# STM32H745BGT6@M4 register map
File version: 1.0
Registers are 32-bit, access not given, reset 0x0 unless marked. A register's access mark holds for its fields unless they carry their own. Offsets are from the block's base; [hi:lo] are bit positions; {n}, {i} and the like mark numbered series.

## QUADSPI
Base 0x52005000
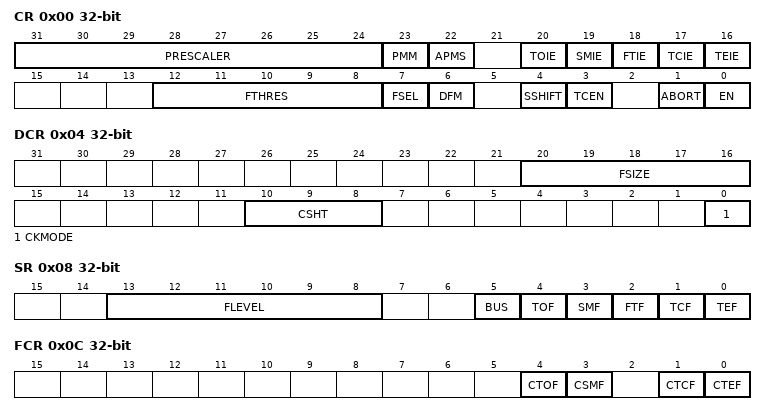
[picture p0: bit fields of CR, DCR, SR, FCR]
0x00 CR
  [31:24] PRESCALER, [23] PMM, [22] APMS, [20] TOIE, [19] SMIE, [18] FTIE, [17] TCIE, [16] TEIE, [12:8] FTHRES, [7] FSEL, [6] DFM, [4] SSHIFT, [3] TCEN, [1] ABORT, [0] EN
0x04 DCR
  [20:16] FSIZE, [10:8] CSHT, [0] CKMODE
0x08 SR
  [13:8] FLEVEL, [5] BUS, [4] TOF, [3] SMF, [2] FTF, [1] TCF, [0] TEF
0x0C FCR
  [4] CTOF, [3] CSMF, [1] CTCF, [0] CTEF
0x10 DLR
  [31:0] DL
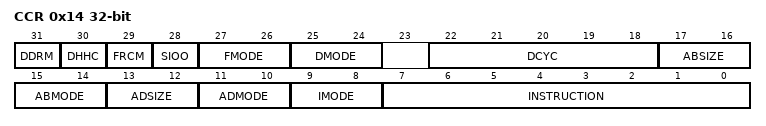
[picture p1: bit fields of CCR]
0x14 CCR
  [31] DDRM, [30] DHHC, [29] FRCM, [28] SIOO, [27:26] FMODE, [25:24] DMODE, [22:18] DCYC, [17:16] ABSIZE, [15:14] ABMODE, [13:12] ADSIZE, [11:10] ADMODE, [9:8] IMODE, [7:0] INSTRUCTION
0x18 AR
  [31:0] ADDRESS
0x1C ABR
  [31:0] ALTERNATE
0x20 DR
  [31:0] DATA
0x24 PSMKR
  [31:0] MASK
0x28 PSMAR
  [31:0] MATCH
0x2C PIR
  [15:0] INTERVAL
0x30 LPTR
  [15:0] TIMEOUT

## EXTI
Base 0x58000000
0x00 RTSR1
  [21:0] TR
0x04 FTSR1
  [21:0] TR
0x08 SWIER1
  [21:0] SWIER
0x0C D3PMR1
  [25:0] MR
0x10 D3PCR1L
  [31:0] PCS
0x14 D3PCR1H
  [19:6] PCS
0x20 RTSR2
  [19:17] TR
0x24 FTSR2
  [19:17] TR
0x28 SWIER2
  [19:17] SWIER
0x2C D3PMR2
  [21:2] MR
0x30 D3PCR2L
  [19:4] PCS
0x34 D3PCR2H
  [11:0] PCS
0x40 RTSR3
  [22:18] TR
0x44 FTSR3
  [22:18] TR
0x48 SWIER3
  [22:18] SWIER
0x4C D3PMR3
  [24] MR
0x50 D3PCR3L
0x54 D3PCR3H
  [17:16] PCS
0x80 C1IMR1
  [31:0] MR
0x84 C1EMR1
  [31:0] MR
0x88 C1PR1
  [21:0] PR
0x90 C1IMR2
  [31:0] MR
0x94 C1EMR2
  [31:0] MR
0x98 C1PR2
  [19:17] PR
0xA0 C1IMR3
  [24:0] MR
0xA4 C1EMR3
  [24:0] MR
0xA8 C1PR3
  [22:18] PR
0xC0 C2IMR1
  [31:0] MR
0xC4 C2EMR1
  [31:0] MR
0xC8 C2PR1
  [21:0] PR
0xD0 C2IMR2
  [31:0] MR
0xD4 C2EMR2
  [31:0] MR
0xD8 C2PR2
  [19:17] PR
0xE0 C2IMR3
  [24:0] MR
0xE4 C2EMR3
  [24:0] MR
0xE8 C2PR3
  [22:18] PR

## SYSCFG
Base 0x58000400
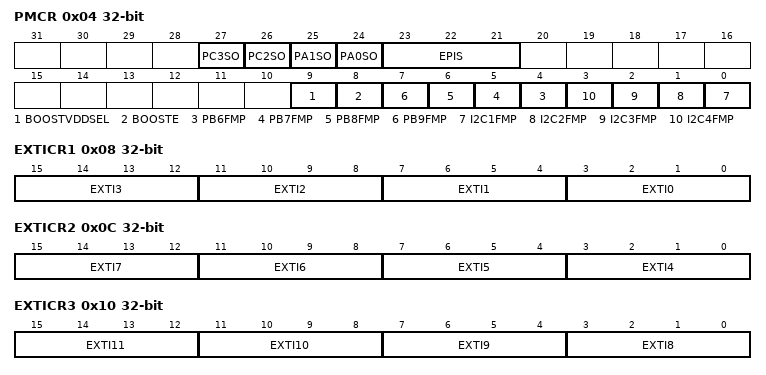
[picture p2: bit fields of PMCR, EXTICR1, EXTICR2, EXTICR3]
0x04 PMCR
  [27] PC3SO, [26] PC2SO, [25] PA1SO, [24] PA0SO, [23:21] EPIS, [9] BOOSTVDDSEL, [8] BOOSTE, [n-2] PB{n}FMP (n=6..9), [n-1] I2C{n}FMP (n=1..4)
0x08 EXTICR1
  [4n+3:4n] EXTI{n} (n=0..3)
0x0C EXTICR2
  [4n-13:4n-16] EXTI{n} (n=4..7)
0x10 EXTICR3
  [4n-29:4n-32] EXTI{n} (n=8..11)
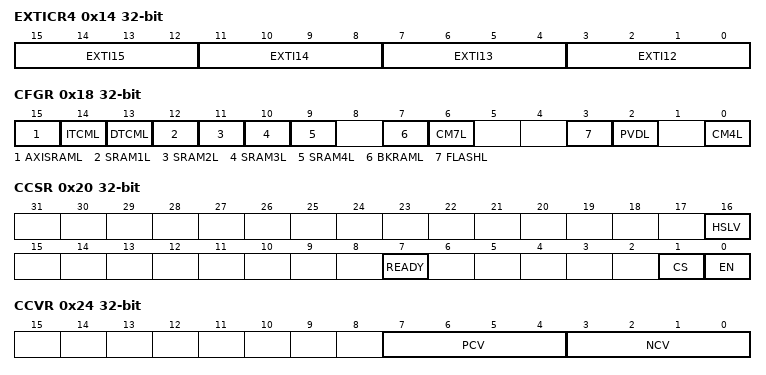
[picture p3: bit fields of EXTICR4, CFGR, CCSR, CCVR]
0x14 EXTICR4
  [4n-45:4n-48] EXTI{n} (n=12..15)
0x18 CFGR
  [15] AXISRAML, [14] ITCML, [13] DTCML, [13-n] SRAM{n}L (n=1..4), [7] BKRAML, [6] CM7L, [3] FLASHL, [2] PVDL, [0] CM4L
0x20 CCSR
  [16] HSLV, [7] READY, [1] CS, [0] EN
0x24 CCVR
  [7:4] PCV, [3:0] NCV
0x2C CCCR
  [0] ODEN
0x124 PKGR
  [3:0] PKG
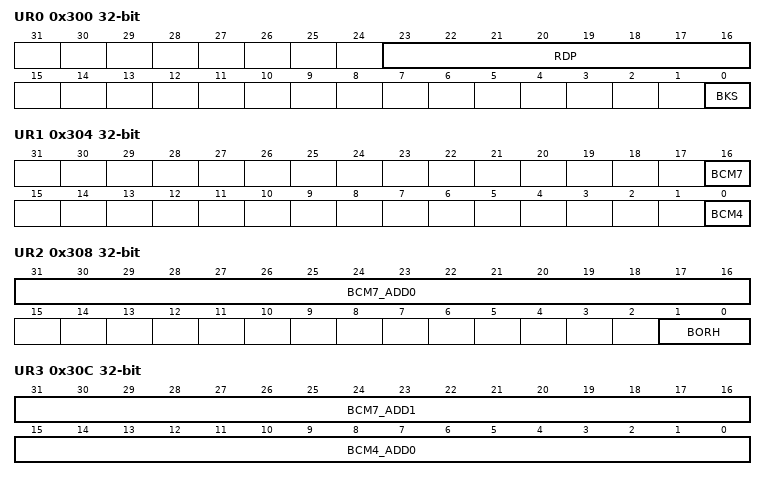
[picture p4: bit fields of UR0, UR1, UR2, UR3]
0x300 UR0
  [23:16] RDP, [0] BKS
0x304 UR1
  [16] BCM7, [0] BCM4
0x308 UR2
  [31:16] BCM7_ADD0, [1:0] BORH
0x30C UR3
  [31:16] BCM7_ADD1, [15:0] BCM4_ADD0
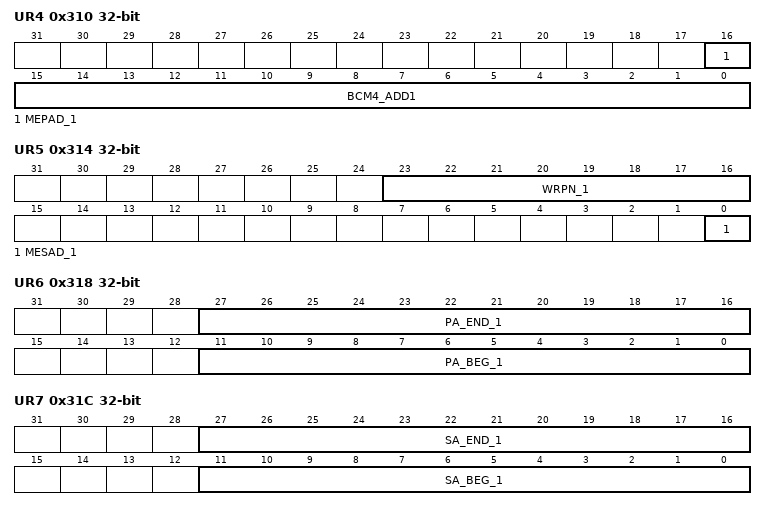
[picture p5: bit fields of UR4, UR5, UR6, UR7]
0x310 UR4
  [16] MEPAD_1, [15:0] BCM4_ADD1
0x314 UR5
  [23:16] WRPN_1, [0] MESAD_1
0x318 UR6
  [27:16] PA_END_1, [11:0] PA_BEG_1
0x31C UR7
  [27:16] SA_END_1, [11:0] SA_BEG_1
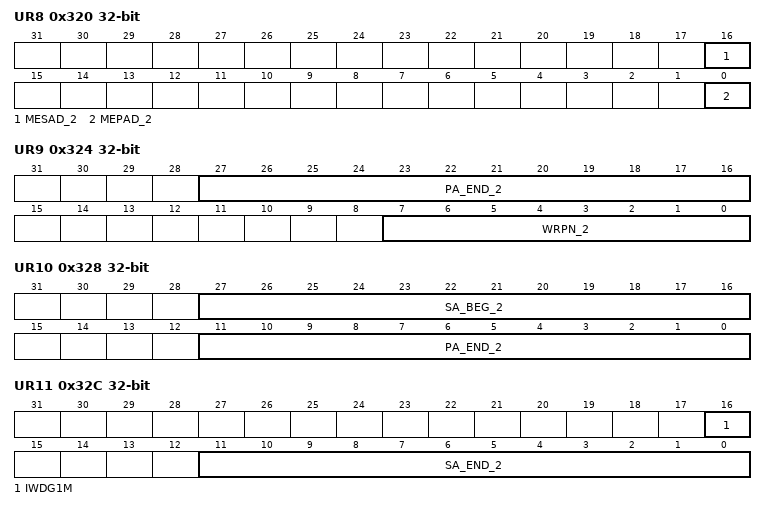
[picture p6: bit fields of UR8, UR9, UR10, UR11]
0x320 UR8
  [16] MESAD_2, [0] MEPAD_2
0x324 UR9
  [27:16] PA_END_2, [7:0] WRPN_2
0x328 UR10
  [27:16] SA_BEG_2, [11:0] PA_END_2
0x32C UR11
  [16] IWDG1M, [11:0] SA_END_2
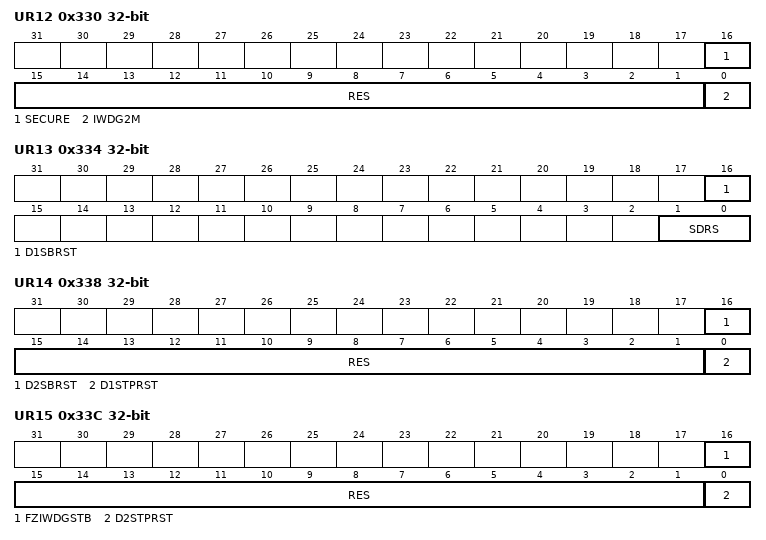
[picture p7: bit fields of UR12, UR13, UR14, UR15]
0x330 UR12
  [16] SECURE, [15:1] RES, [0] IWDG2M
0x334 UR13
  [16] D1SBRST, [1:0] SDRS
0x338 UR14
  [16] D2SBRST, [15:1] RES, [0] D1STPRST
0x33C UR15
  [16] FZIWDGSTB, [15:1] RES, [0] D2STPRST
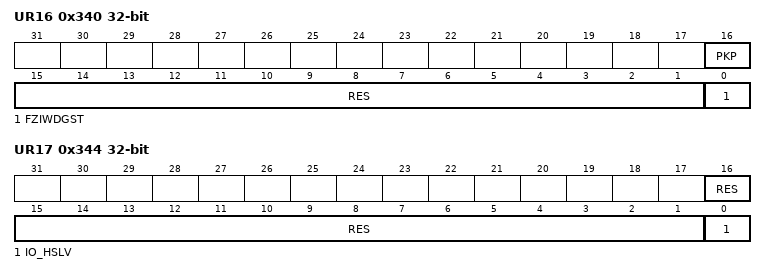
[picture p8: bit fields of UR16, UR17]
0x340 UR16
  [16] PKP, [15:1] RES, [0] FZIWDGST
0x344 UR17
  [16:1] RES, [0] IO_HSLV

## LPUART1
Base 0x58000C00
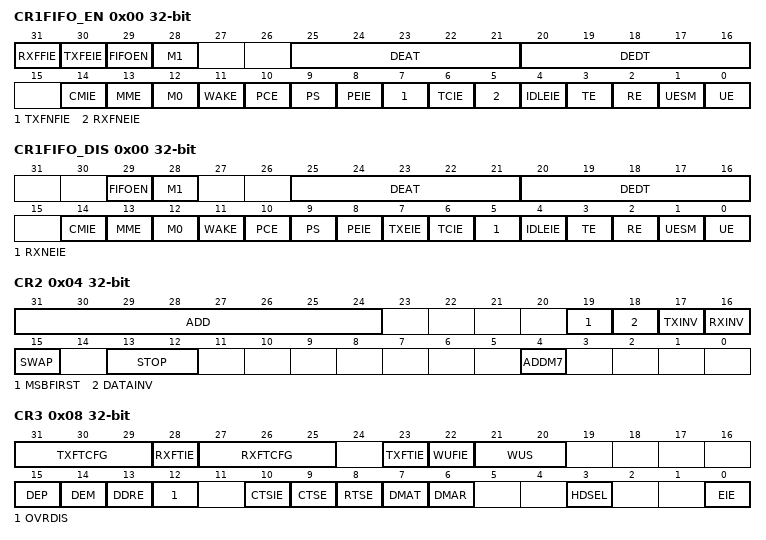
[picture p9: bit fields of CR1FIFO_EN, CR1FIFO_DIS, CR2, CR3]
0x00 CR1FIFO_EN
  [31] RXFFIE, [30] TXFEIE, [29] FIFOEN, [28] M1, [25:21] DEAT, [20:16] DEDT, [14] CMIE, [13] MME, [12] M0, [11] WAKE, [10] PCE, [9] PS, [8] PEIE, [7] TXFNFIE, [6] TCIE, [5] RXFNEIE, [4] IDLEIE, [3] TE, [2] RE, [1] UESM, [0] UE
0x00 CR1FIFO_DIS
  [29] FIFOEN, [28] M1, [25:21] DEAT, [20:16] DEDT, [14] CMIE, [13] MME, [12] M0, [11] WAKE, [10] PCE, [9] PS, [8] PEIE, [7] TXEIE, [6] TCIE, [5] RXNEIE, [4] IDLEIE, [3] TE, [2] RE, [1] UESM, [0] UE
0x04 CR2
  [31:24] ADD, [19] MSBFIRST, [18] DATAINV, [17] TXINV, [16] RXINV, [15] SWAP, [13:12] STOP, [4] ADDM7
0x08 CR3
  [31:29] TXFTCFG, [28] RXFTIE, [27:25] RXFTCFG, [23] TXFTIE, [22] WUFIE, [21:20] WUS, [15] DEP, [14] DEM, [13] DDRE, [12] OVRDIS, [10] CTSIE, [9] CTSE, [8] RTSE, [7] DMAT, [6] DMAR, [3] HDSEL, [0] EIE
0x0C BRR
  [19:0] BRR
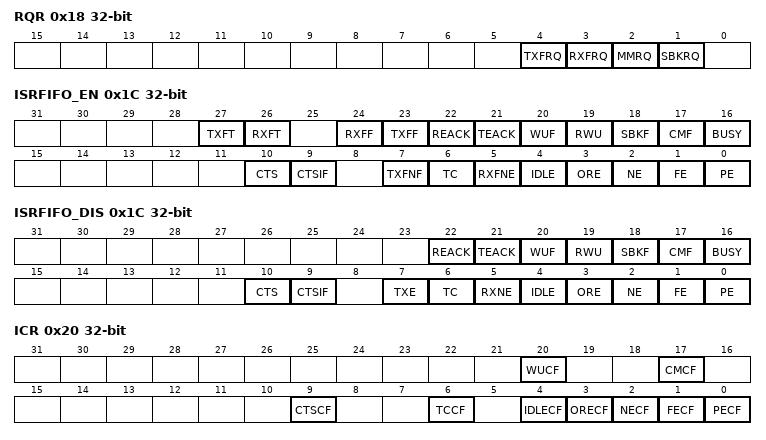
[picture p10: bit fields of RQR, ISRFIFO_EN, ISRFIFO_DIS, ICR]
0x18 RQR
  [4] TXFRQ, [3] RXFRQ, [2] MMRQ, [1] SBKRQ
0x1C ISRFIFO_EN
  [27] TXFT, [26] RXFT, [24] RXFF, [23] TXFF, [22] REACK, [21] TEACK, [20] WUF, [19] RWU, [18] SBKF, [17] CMF, [16] BUSY, [10] CTS, [9] CTSIF, [7] TXFNF, [6] TC, [5] RXFNE, [4] IDLE, [3] ORE, [2] NE, [1] FE, [0] PE
0x1C ISRFIFO_DIS
  [22] REACK, [21] TEACK, [20] WUF, [19] RWU, [18] SBKF, [17] CMF, [16] BUSY, [10] CTS, [9] CTSIF, [7] TXE, [6] TC, [5] RXNE, [4] IDLE, [3] ORE, [2] NE, [1] FE, [0] PE
0x20 ICR
  [20] WUCF, [17] CMCF, [9] CTSCF, [6] TCCF, [4] IDLECF, [3] ORECF, [2] NECF, [1] FECF, [0] PECF
0x24 RDR
  [8:0] RDR
0x28 TDR
  [8:0] TDR
0x2C PRESC
  [3:0] PRESCALER
